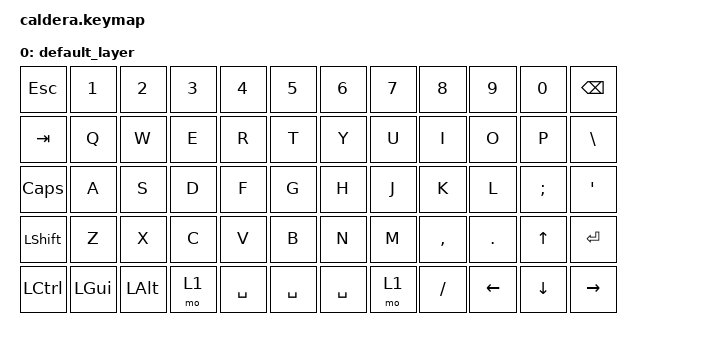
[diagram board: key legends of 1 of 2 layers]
#include <behaviors.dtsi>
#include <dt-bindings/zmk/bt.h>
#include <dt-bindings/zmk/keys.h>

/ {
    keymap {
        compatible = "zmk,keymap";

        default_layer {
            // ---------------------------------------------------------------------------------
            // |  ESC |  1  |  2  |  3  |  4  |  5  |     |  6  |  7  |  8  |  9  |  0  | BKSP |
            // |  TAB |  Q  |  W  |  E  |  R  |  T  |     |  Y  |  U  |  I  |  O  |  P  |  \   |
            // | CAPS |  A  |  S  |  D  |  F  |  G  |     |  H  |  J  |  K  |  L  |  ;  |  ENT |
            // | SHFT |  Z  |  X  |  C  |  V  |  B  |     |  N  |  M  |  ,  |  .  |  /  | APOS |
            // | CTRL | ALT | GUI | SPC | ALT | GUI |     | SPC | LOW |LARW |DARW |UARW | RARW |

            bindings = <
&kp ESC    &kp N1    &kp N2    &kp N3  &kp N4     &kp N5       &kp N6     &kp N7  &kp N8     &kp N9          &kp N0          &kp BSPC
&kp TAB    &kp Q     &kp W     &kp E   &kp R      &kp T        &kp Y      &kp U   &kp I      &kp O           &kp P           &kp BSLH
&kp CAPS   &kp A     &kp S     &kp D   &kp F      &kp G        &kp H      &kp J   &kp K      &kp L           &kp SEMI        &kp APOS
&kp LSHFT  &kp Z     &kp X     &kp C   &kp V      &kp B        &kp N      &kp M   &kp COMMA  &kp DOT         &kp UP_ARROW    &kp RETURN
&kp LCTRL  &kp LGUI  &kp LALT  &mo 1   &kp SPACE  &kp SPACE    &kp SPACE  &mo 1   &kp FSLH   &kp LEFT_ARROW  &kp DOWN_ARROW  &kp RIGHT_ARROW
            >;
        };

        lower_layer {
            // ------------------------------------------------------------------------------------------------------------
            // |       |  BT1  |  BT2  |  BT3  |  BT4  |  BT5  |          |       |       |       |       |       | BTCLR |
            // |       |       |       |       |       |       |          |       |       |       |       |       |       |
            // |       |       |       | LPAR  | RPAR  |       |          |       | LBKT  | RBKT  |   -   |   =   |       |
            // |       |       |       |       |       |       |          |       |       |       |       |       |       |

            bindings = <
&trans  &bt BT_SEL 0  &bt BT_SEL 1   &bt BT_SEL 2   &bt BT_SEL 3  &bt BT_SEL 4    &trans     &trans    &trans    &trans       &trans     &bt BT_CLR
&trans  &trans        &trans         &trans         &trans        &trans          &trans     &kp F4    &kp F11   &kp LC(F11)  &trans     &trans
&trans  &trans        &kp LS(LG(Z))  &kp LS(LG(S))  &kp LPAR      &kp RPAR        &trans     &kp LBKT  &kp RBKT  &kp MINUS    &kp EQUAL  &kp RET
&trans  &trans        &trans         &trans         &trans        &kp SPACE       &kp SPACE  &trans    &trans    &trans       &trans     &trans
            >;
        };
    };
};
